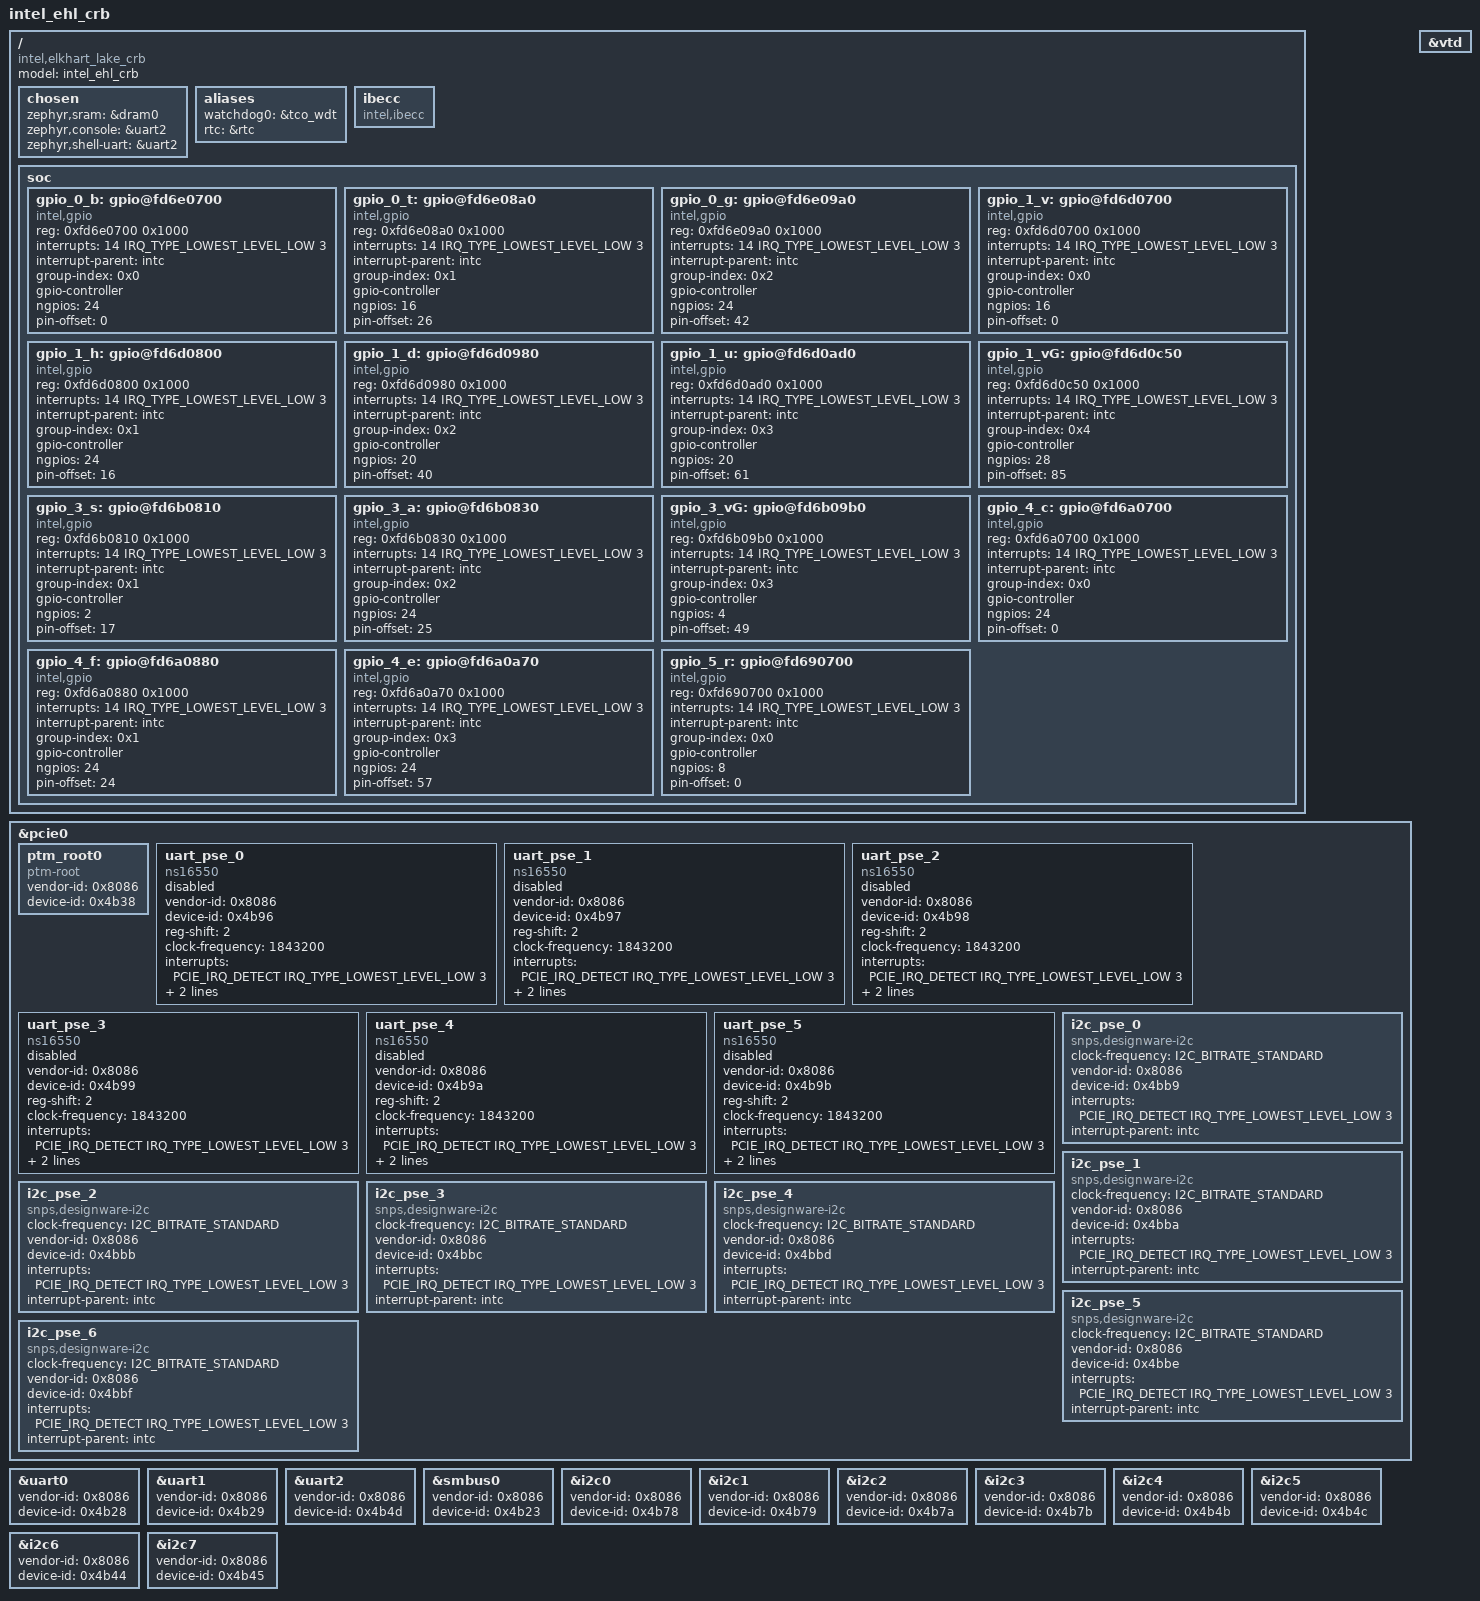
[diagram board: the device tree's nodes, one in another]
/*
 * Copyright (c) 2020 Intel Corporation
 *
 * SPDX-License-Identifier: Apache-2.0
 */

/dts-v1/;

#include <mem.h>

#define DT_DRAM_SIZE		DT_SIZE_M(2048)

#include <intel/x86_64.dtsi>

/ {
	model = "intel_ehl_crb";
	compatible = "intel,elkhart_lake_crb";

	chosen {
		zephyr,sram = &dram0;
		zephyr,console = &uart2;
		zephyr,shell-uart = &uart2;
	};

	aliases {
		watchdog0 = &tco_wdt;
		rtc = &rtc;
	};

	ibecc: ibecc {
	       compatible = "intel,ibecc";
	       status = "okay";
	};

	soc {
		gpio_0_b: gpio@fd6e0700 {
			compatible = "intel,gpio";
			reg = <0xfd6e0700 0x1000>;
			interrupts = <14 IRQ_TYPE_LOWEST_LEVEL_LOW 3>;
			interrupt-parent = <&intc>;

			group-index = <0x0>;
			gpio-controller;
			#gpio-cells = <2>;

			ngpios = <24>;
			pin-offset = <0>;

			status = "okay";
		};

		gpio_0_t: gpio@fd6e08a0 {
			compatible = "intel,gpio";
			reg = <0xfd6e08a0 0x1000>;
			interrupts = <14 IRQ_TYPE_LOWEST_LEVEL_LOW 3>;
			interrupt-parent = <&intc>;

			group-index = <0x1>;
			gpio-controller;
			#gpio-cells = <2>;

			ngpios = <16>;
			pin-offset = <26>;

			status = "okay";
		};

		gpio_0_g: gpio@fd6e09a0 {
			compatible = "intel,gpio";
			reg = <0xfd6e09a0 0x1000>;
			interrupts = <14 IRQ_TYPE_LOWEST_LEVEL_LOW 3>;
			interrupt-parent = <&intc>;

			group-index = <0x2>;
			gpio-controller;
			#gpio-cells = <2>;

			ngpios = <24>;
			pin-offset = <42>;

			status = "okay";
		};

		gpio_1_v: gpio@fd6d0700 {
			compatible = "intel,gpio";
			reg = <0xfd6d0700 0x1000>;
			interrupts = <14 IRQ_TYPE_LOWEST_LEVEL_LOW 3>;
			interrupt-parent = <&intc>;

			group-index = <0x0>;
			gpio-controller;
			#gpio-cells = <2>;

			ngpios = <16>;
			pin-offset = <0>;

			status = "okay";
		};

		gpio_1_h: gpio@fd6d0800 {
			compatible = "intel,gpio";
			reg = <0xfd6d0800 0x1000>;
			interrupts = <14 IRQ_TYPE_LOWEST_LEVEL_LOW 3>;
			interrupt-parent = <&intc>;

			group-index = <0x1>;
			gpio-controller;
			#gpio-cells = <2>;

			ngpios = <24>;
			pin-offset = <16>;

			status = "okay";
		};

		gpio_1_d: gpio@fd6d0980 {
			compatible = "intel,gpio";
			reg = <0xfd6d0980 0x1000>;
			interrupts = <14 IRQ_TYPE_LOWEST_LEVEL_LOW 3>;
			interrupt-parent = <&intc>;

			group-index = <0x2>;
			gpio-controller;
			#gpio-cells = <2>;

			ngpios = <20>;
			pin-offset = <40>;

			status = "okay";
		};

		gpio_1_u: gpio@fd6d0ad0 {
			compatible = "intel,gpio";
			reg = <0xfd6d0ad0 0x1000>;
			interrupts = <14 IRQ_TYPE_LOWEST_LEVEL_LOW 3>;
			interrupt-parent = <&intc>;

			group-index = <0x3>;
			gpio-controller;
			#gpio-cells = <2>;

			ngpios = <20>;
			pin-offset = <61>;

			status = "okay";
		};

		gpio_1_vG: gpio@fd6d0c50 {
			compatible = "intel,gpio";
			reg = <0xfd6d0c50 0x1000>;
			interrupts = <14 IRQ_TYPE_LOWEST_LEVEL_LOW 3>;
			interrupt-parent = <&intc>;

			group-index = <0x4>;
			gpio-controller;
			#gpio-cells = <2>;

			ngpios = <28>;
			pin-offset = <85>;

			status = "okay";
		};

		gpio_3_s: gpio@fd6b0810 {
			compatible = "intel,gpio";
			reg = <0xfd6b0810 0x1000>;
			interrupts = <14 IRQ_TYPE_LOWEST_LEVEL_LOW 3>;
			interrupt-parent = <&intc>;

			group-index = <0x1>;
			gpio-controller;
			#gpio-cells = <2>;

			ngpios = <2>;
			pin-offset = <17>;

			status = "okay";
		};

		gpio_3_a: gpio@fd6b0830 {
			compatible = "intel,gpio";
			reg = <0xfd6b0830 0x1000>;
			interrupts = <14 IRQ_TYPE_LOWEST_LEVEL_LOW 3>;
			interrupt-parent = <&intc>;

			group-index = <0x2>;
			gpio-controller;
			#gpio-cells = <2>;

			ngpios = <24>;
			pin-offset = <25>;

			status = "okay";
		};

		gpio_3_vG: gpio@fd6b09b0 {
			compatible = "intel,gpio";
			reg = <0xfd6b09b0 0x1000>;
			interrupts = <14 IRQ_TYPE_LOWEST_LEVEL_LOW 3>;
			interrupt-parent = <&intc>;

			group-index = <0x3>;
			gpio-controller;
			#gpio-cells = <2>;

			ngpios = <4>;
			pin-offset = <49>;

			status = "okay";
		};

		gpio_4_c: gpio@fd6a0700 {
			compatible = "intel,gpio";
			reg = <0xfd6a0700 0x1000>;
			interrupts = <14 IRQ_TYPE_LOWEST_LEVEL_LOW 3>;
			interrupt-parent = <&intc>;

			group-index = <0x0>;
			gpio-controller;
			#gpio-cells = <2>;

			ngpios = <24>;
			pin-offset = <0>;

			status = "okay";
		};

		gpio_4_f: gpio@fd6a0880 {
			compatible = "intel,gpio";
			reg = <0xfd6a0880 0x1000>;
			interrupts = <14 IRQ_TYPE_LOWEST_LEVEL_LOW 3>;
			interrupt-parent = <&intc>;

			group-index = <0x1>;
			gpio-controller;
			#gpio-cells = <2>;

			ngpios = <24>;
			pin-offset = <24>;

			status = "okay";
		};

		gpio_4_e: gpio@fd6a0a70 {
			compatible = "intel,gpio";
			reg = <0xfd6a0a70 0x1000>;
			interrupts = <14 IRQ_TYPE_LOWEST_LEVEL_LOW 3>;
			interrupt-parent = <&intc>;

			group-index = <0x3>;
			gpio-controller;
			#gpio-cells = <2>;

			ngpios = <24>;
			pin-offset = <57>;

			status = "okay";
		};

		gpio_5_r: gpio@fd690700 {
			compatible = "intel,gpio";
			reg = <0xfd690700 0x1000>;
			interrupts = <14 IRQ_TYPE_LOWEST_LEVEL_LOW 3>;
			interrupt-parent = <&intc>;

			group-index = <0x0>;
			gpio-controller;
			#gpio-cells = <2>;

			ngpios = <8>;
			pin-offset = <0>;

			status = "okay";
		};
	};
};

&pcie0 {
	ptm_root0: ptm_root0 {
		compatible = "ptm-root";
		vendor-id = <0x8086>;
		device-id = <0x4b38>;

		status = "okay";
	};

	uart_pse_0: uart_pse_0 {
		compatible = "ns16550";

		vendor-id = <0x8086>;
		device-id = <0x4b96>;

		reg-shift = <2>;
		clock-frequency = <1843200>;
		interrupts = <PCIE_IRQ_DETECT IRQ_TYPE_LOWEST_LEVEL_LOW 3>;
		interrupt-parent = <&intc>;

		status = "disabled";
		current-speed = <115200>;
	};

	uart_pse_1: uart_pse_1 {
		compatible = "ns16550";

		vendor-id = <0x8086>;
		device-id = <0x4b97>;

		reg-shift = <2>;
		clock-frequency = <1843200>;
		interrupts = <PCIE_IRQ_DETECT IRQ_TYPE_LOWEST_LEVEL_LOW 3>;
		interrupt-parent = <&intc>;

		status = "disabled";
		current-speed = <115200>;
	};

	uart_pse_2: uart_pse_2 {
		compatible = "ns16550";

		vendor-id = <0x8086>;
		device-id = <0x4b98>;

		reg-shift = <2>;
		clock-frequency = <1843200>;
		interrupts = <PCIE_IRQ_DETECT IRQ_TYPE_LOWEST_LEVEL_LOW 3>;
		interrupt-parent = <&intc>;

		status = "disabled";
		current-speed = <115200>;
	};

	uart_pse_3: uart_pse_3 {
		compatible = "ns16550";

		vendor-id = <0x8086>;
		device-id = <0x4b99>;

		reg-shift = <2>;
		clock-frequency = <1843200>;
		interrupts = <PCIE_IRQ_DETECT IRQ_TYPE_LOWEST_LEVEL_LOW 3>;
		interrupt-parent = <&intc>;

		status = "disabled";
		current-speed = <115200>;
	};

	uart_pse_4: uart_pse_4 {
		compatible = "ns16550";

		vendor-id = <0x8086>;
		device-id = <0x4b9a>;

		reg-shift = <2>;
		clock-frequency = <1843200>;
		interrupts = <PCIE_IRQ_DETECT IRQ_TYPE_LOWEST_LEVEL_LOW 3>;
		interrupt-parent = <&intc>;

		status = "disabled";
		current-speed = <115200>;
	};

	uart_pse_5: uart_pse_5 {
		compatible = "ns16550";

		vendor-id = <0x8086>;
		device-id = <0x4b9b>;

		reg-shift = <2>;
		clock-frequency = <1843200>;
		interrupts = <PCIE_IRQ_DETECT IRQ_TYPE_LOWEST_LEVEL_LOW 3>;
		interrupt-parent = <&intc>;

		status = "disabled";
		current-speed = <115200>;
	};

	i2c_pse_0: i2c_pse_0 {
		compatible = "snps,designware-i2c";
		clock-frequency = <I2C_BITRATE_STANDARD>;
		#address-cells = <1>;
		#size-cells = <0>;
		vendor-id = <0x8086>;
		device-id = <0x4bb9>;
		interrupts = <PCIE_IRQ_DETECT IRQ_TYPE_LOWEST_LEVEL_LOW 3>;
		interrupt-parent = <&intc>;

		status = "okay";
	};

	i2c_pse_1: i2c_pse_1 {
		compatible = "snps,designware-i2c";
		clock-frequency = <I2C_BITRATE_STANDARD>;
		#address-cells = <1>;
		#size-cells = <0>;
		vendor-id = <0x8086>;
		device-id = <0x4bba>;
		interrupts = <PCIE_IRQ_DETECT IRQ_TYPE_LOWEST_LEVEL_LOW 3>;
		interrupt-parent = <&intc>;

		status = "okay";
	};

	i2c_pse_2: i2c_pse_2 {
		compatible = "snps,designware-i2c";
		clock-frequency = <I2C_BITRATE_STANDARD>;
		#address-cells = <1>;
		#size-cells = <0>;
		vendor-id = <0x8086>;
		device-id = <0x4bbb>;
		interrupts = <PCIE_IRQ_DETECT IRQ_TYPE_LOWEST_LEVEL_LOW 3>;
		interrupt-parent = <&intc>;

		status = "okay";
	};

	i2c_pse_3: i2c_pse_3 {
		compatible = "snps,designware-i2c";
		clock-frequency = <I2C_BITRATE_STANDARD>;
		#address-cells = <1>;
		#size-cells = <0>;
		vendor-id = <0x8086>;
		device-id = <0x4bbc>;
		interrupts = <PCIE_IRQ_DETECT IRQ_TYPE_LOWEST_LEVEL_LOW 3>;
		interrupt-parent = <&intc>;

		status = "okay";
	};

	i2c_pse_4: i2c_pse_4 {
		compatible = "snps,designware-i2c";
		clock-frequency = <I2C_BITRATE_STANDARD>;
		#address-cells = <1>;
		#size-cells = <0>;
		vendor-id = <0x8086>;
		device-id = <0x4bbd>;
		interrupts = <PCIE_IRQ_DETECT IRQ_TYPE_LOWEST_LEVEL_LOW 3>;
		interrupt-parent = <&intc>;

		status = "okay";
	};

	i2c_pse_5: i2c_pse_5 {
		compatible = "snps,designware-i2c";
		clock-frequency = <I2C_BITRATE_STANDARD>;
		#address-cells = <1>;
		#size-cells = <0>;
		vendor-id = <0x8086>;
		device-id = <0x4bbe>;
		interrupts = <PCIE_IRQ_DETECT IRQ_TYPE_LOWEST_LEVEL_LOW 3>;
		interrupt-parent = <&intc>;

		status = "okay";
	};

	i2c_pse_6: i2c_pse_6 {
		compatible = "snps,designware-i2c";
		clock-frequency = <I2C_BITRATE_STANDARD>;
		#address-cells = <1>;
		#size-cells = <0>;
		vendor-id = <0x8086>;
		device-id = <0x4bbf>;
		interrupts = <PCIE_IRQ_DETECT IRQ_TYPE_LOWEST_LEVEL_LOW 3>;
		interrupt-parent = <&intc>;

		status = "okay";
	};
};

&uart0 {
	vendor-id = <0x8086>;
	device-id = <0x4b28>;

	status = "okay";
};

&uart1 {
	vendor-id = <0x8086>;
	device-id = <0x4b29>;

	status = "okay";
};

&uart2 {
	vendor-id = <0x8086>;
	device-id = <0x4b4d>;

	status = "okay";
};

&smbus0 {
	vendor-id = <0x8086>;
	device-id = <0x4b23>;

	status = "okay";
};

&i2c0 {
	vendor-id = <0x8086>;
	device-id = <0x4b78>;

	status = "okay";
};

&i2c1 {
	vendor-id = <0x8086>;
	device-id = <0x4b79>;

	status = "okay";
};

&i2c2 {
	vendor-id = <0x8086>;
	device-id = <0x4b7a>;

	status = "okay";
};

&i2c3 {
	vendor-id = <0x8086>;
	device-id = <0x4b7b>;

	status = "okay";
};

&i2c4 {
	vendor-id = <0x8086>;
	device-id = <0x4b4b>;

	status = "okay";
};

&i2c5 {
	vendor-id = <0x8086>;
	device-id = <0x4b4c>;

	status = "okay";
};

&i2c6 {
	vendor-id = <0x8086>;
	device-id = <0x4b44>;

	status = "okay";
};

&i2c7 {
	vendor-id = <0x8086>;
	device-id = <0x4b45>;

	status = "okay";
};

&vtd {
	status = "okay";
};
